# R7FA6T1AD register map
Vendor: Renesas; Series: RA6; File version: 1.0
CPU: CM4 r0p1, little endian, MPU, FPU, VTOR, 4 interrupt priority bits
Registers are 8-bit, read-write, reset 0x0 unless marked. A register's access mark holds for its fields unless they carry their own. Offsets are from the block's base; [hi:lo] are bit positions; {n}, {i} and the like mark numbered series; 'fields as' and 'values as' point back to an identical list.

## PMISC — Miscellaneous Port Control Register
Base 0x40040D00
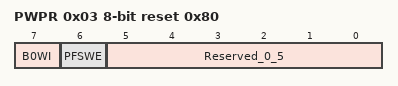
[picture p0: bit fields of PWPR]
0x03 PWPR reset 0x80 — Write,Protect Register
  [7] B0WI — PFSWE Bit Write Disable
  [6] PFSWE — PFS Register Write Enable
  [5:0] Reserved_0_5 — These bits are read as 000000. The write value should be 000000.

## MMPU — Bus Master MPU
Base 0x40000000
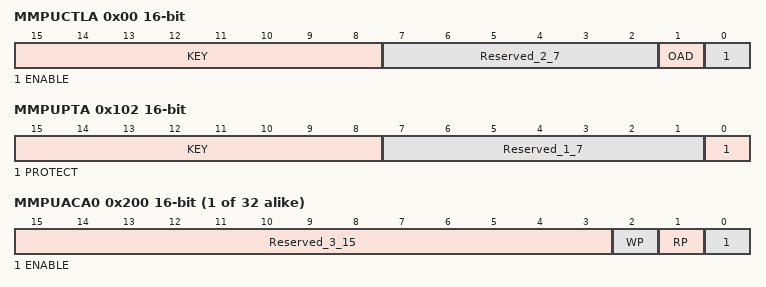
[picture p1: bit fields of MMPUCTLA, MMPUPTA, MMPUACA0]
0x00 MMPUCTLA 16-bit — Bus Master MPU Control Register
  [15:8] KEY wo — Write Keyword The data written to these bits are not stored.
  [7:2] Reserved_2_7 — These bits are read as 000000. The write value should be 000000.
  [1] OAD — Operation After Detection
  [0] ENABLE — Master Group Enable
0x102 MMPUPTA 16-bit — Group A Protection of Register
  [15:8] KEY wo — Write Keyword The data written to these bits are not stored.
  [7:1] Reserved_1_7 — These bits are read as 0000000. The write value should be 0000000.
  [0] PROTECT — Protection of register (MMPUSAn, MMPUEAn, MMPUACAn and MMPUCTLA )
{0x200+0x10*i} MMPUACA{i} (i=0..31) 16-bit — Group A Region {i} Access Control Register
  [15:3] Reserved_3_15 — These bits are read as 0000000000000. The write value should be 0000000000000.
  [2] WP — Write protection
  [1] RP — Read protection
  [0] ENABLE — Region enable
{0x204+0x10*i} MMPUSA{i} (i=0..31) 32-bit (reset mask 0x3) — Group A Region {i} Start Address Register
  [31:0] MMPUSA — Region Stat Address : Address where the region starts, for use in region determination. NOTE: The low,order 2 bits are fixed to 0.
{0x208+0x10*i} MMPUEA{i} (i=0..31) 32-bit reset 0x3 (reset mask 0x3) — Group A Region {i} End Address Register
  [31:0] MMPUEA — Region End Address : Address where the region end, for use in region determination. NOTE: The low,order 2 bits are fixed to 1.

## SMPU — Bus Slave MPU
Base 0x40000C00
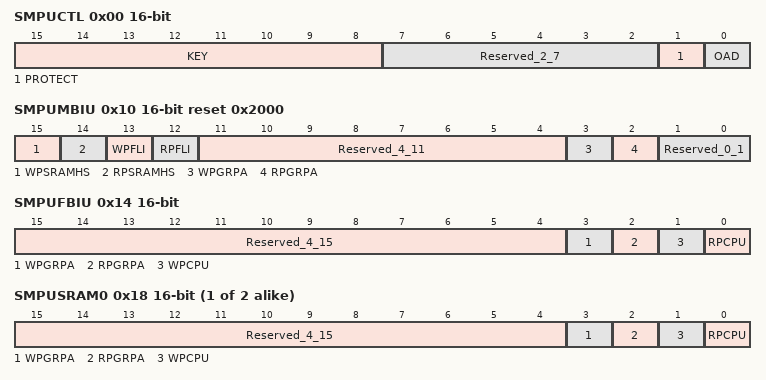
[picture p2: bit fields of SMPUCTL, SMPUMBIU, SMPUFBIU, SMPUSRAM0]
0x00 SMPUCTL 16-bit — Slave MPU Control Register
  [15:8] KEY wo — Key Code This bit is used to enable or disable writing of the PROTECT and OAD bit.
  [7:2] Reserved_2_7 — These bits are read as 000000. The write value should be 000000.
  [1] PROTECT — Protection of register
  [0] OAD — Operation after detection
0x10 SMPUMBIU 16-bit reset 0x2000 — Access Control Register for MBIU
  [15] WPSRAMHS — SRAMHS Write Protection
  [14] RPSRAMHS — SRAMHS Read Protection
  [13] WPFLI — Code Flash Memory Write Protection (Note: This bit is read as 1. The write value should be 1.)
  [12] RPFLI — Code Flash Memory Read Protection
  [11:4] Reserved_4_11 — These bits are read as 00000000. The write value should be 00000000.
  [3] WPGRPA — Master Group A Write protection
  [2] RPGRPA — Master Group A Read protection
  [1:0] Reserved_0_1 — These bits are read as 00. The write value should be 00.
0x14 SMPUFBIU 16-bit — Access Control Register for FBIU
  [15:4] Reserved_4_15 — These bits are read as 000000000000. The write value should be 000000000000.
  [3] WPGRPA — Master Group A Write protection
  [2] RPGRPA — Master Group A Read protection
  [1] WPCPU — CPU Write protection
  [0] RPCPU — CPU Read protection
{0x18+4i} SMPUSRAM{i} (i=0..1) 16-bit — Access Control Register for SRAM{i}
  fields as SMPUFBIU
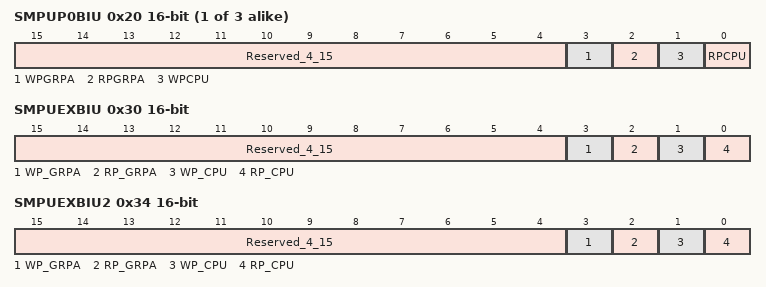
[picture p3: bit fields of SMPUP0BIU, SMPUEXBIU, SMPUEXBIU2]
0x20 SMPUP{x}BIU (x=0,2,6; step 0x4) 16-bit — Access Control Register for P{x}BIU
  fields as SMPUFBIU
0x30 SMPUEXBIU 16-bit — Access Control Register for EXBIU
  [15:4] Reserved_4_15 — These bits are read as 000000000000. The write value should be 000000000000.
  [3] WP_GRPA — Master Group A Write protection
  [2] RP_GRPA — Master Group A Read protection
  [1] WP_CPU — CPU Write protection
  [0] RP_CPU — CPU Read protection
0x34 SMPUEXBIU2 16-bit — Access Control Register for EXBIU2
  fields as SMPUEXBIU

## SPMON — CPU Stack Pointer Monitor
Base 0x40000D00
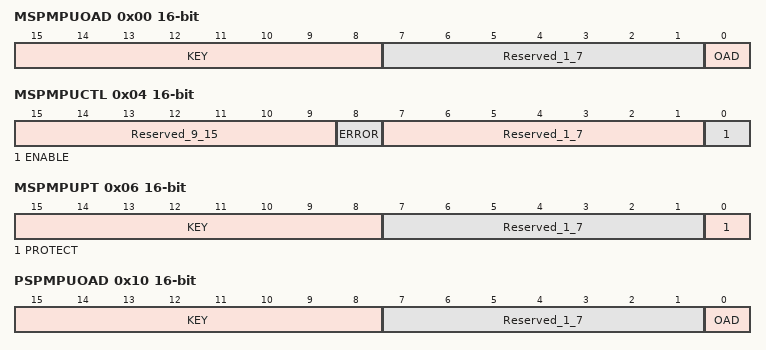
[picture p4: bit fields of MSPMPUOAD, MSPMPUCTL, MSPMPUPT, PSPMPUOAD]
0x00 MSPMPUOAD 16-bit — Stack Pointer Monitor Operation After Detection Register
  [15:8] KEY wo — Write Keyword The data written to these bits are not stored.
  [7:1] Reserved_1_7 — These bits are read as 0000000. The write value should be 0000000.
  [0] OAD — Operation after detection
0x04 MSPMPUCTL 16-bit (reset mask 0xFEFF) — Stack Pointer Monitor Access Control Register
  [15:9] Reserved_9_15 — These bits are read as 0000000. The write value should be 0000000.
  [8] ERROR — Stack Pointer Monitor Error Flag
  [7:1] Reserved_1_7 — These bits are read as 0000000. The write value should be 0000000.
  [0] ENABLE — Stack Pointer Monitor Enable
0x06 MSPMPUPT 16-bit — Stack Pointer Monitor Protection Register
  [15:8] KEY wo — Key Code Write data is not saved.
  [7:1] Reserved_1_7 — These bits are read as 0000000. The write value should be 0000000.
  [0] PROTECT — Protection of register
0x08 MSPMPUSA 32-bit (reset mask 0x3) — Main Stack Pointer Monitor Start Address Register
  [31:0] MSPMPUSA range 0x1FF00000..0x200FFFFC — Region Start Address : Address where the region starts, for use in region determination. NOTE: Range: 0x1FF00000-0x200FFFFC The low,order 2 bits are fixed to 0.
0x0C MSPMPUEA 32-bit reset 0x3 (reset mask 0x3) — Main Stack Pointer Monitor End Address Register
  [31:0] MSPMPUEA range 0x1FF00003..0x200FFFFF — Region End Address : Address where the region ends, for use in region determination. NOTE: Range: 0x1FF00003-0x200FFFFF The low,order 2 bits are fixed to 1.
0x10 PSPMPUOAD 16-bit — Stack Pointer Monitor Operation After Detection Register
  fields as MSPMPUOAD
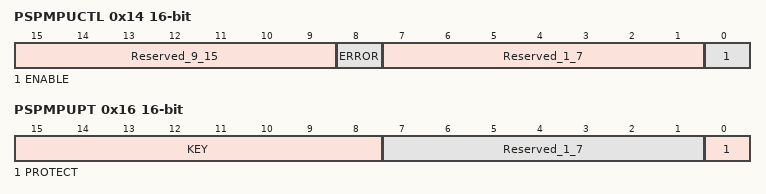
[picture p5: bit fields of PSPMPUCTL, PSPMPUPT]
0x14 PSPMPUCTL 16-bit (reset mask 0xFEFF) — Stack Pointer Monitor Access Control Register
  [15:9] Reserved_9_15 — These bits are read as 0000000. The write value should be 0000000.
  [8] ERROR ro — Stack Pointer Monitor Error Flag
  [7:1] Reserved_1_7 — These bits are read as 0000000. The write value should be 0000000.
  [0] ENABLE — Stack Pointer Monitor Enable
0x16 PSPMPUPT 16-bit — Stack Pointer Monitor Protection Register
  fields as MSPMPUPT
0x18 PSPMPUSA 32-bit (reset mask 0x3) — Process Stack Pointer Monitor Start Address Register
  [31:0] PSPMPUSA range 0x1FF00000..0x200FFFFC — Region Start Address : Address where the region starts, for use in region determination. NOTE: Range: 0x1FF00000-0x200FFFFC The low,order 2 bits are fixed to 0.
0x1C PSPMPUEA 32-bit reset 0x3 (reset mask 0x3) — Process Stack Pointer Monitor End Address Register
  [31:0] PSPMPUEA range 0x1FF00003..0x200FFFFF — Region End Address : Address where the region ends, for use in region determination. NOTE: Range: 0x1FF00003-0x200FFFFF The low,order 2 bits are fixed to 1.

## TSD — Temperature Sensor Data
Base 0x407FB17C
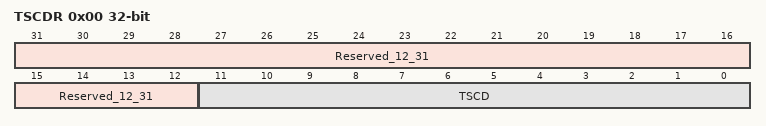
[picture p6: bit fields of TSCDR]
0x00 TSCDR 32-bit ro (reset mask 0xFFFFF000) — Temperature Sensor Calibration Data Register
  [31:12] Reserved_12_31 — These bits are read as 00000000000000000000.
  [11:0] TSCD — Temperature sensor calibration data is a digital value obtained using the 12-bit A/D converter unit 0 to convert the voltage output by the temperature sensor under the condition Ta = Tj = 127°C and AVCC0 = 3.3 V.
